# CH32M030 register map
Vendor: WCH Ltd.; File version: 1.1
CH32M030 View File
Registers are 32-bit, read-write, reset 0x0 unless marked. A register's access mark holds for its fields unless they carry their own. Offsets are from the block's base; lines under a group give offsets from that group; [hi:lo] are bit positions; {n}, {i} and the like mark numbered series; 'fields as' and 'values as' point back to an identical list; <NAME> marks a mode.

## Memory map
0x1FFFF3E0 ESIG size 0x14 — Device electronic signature
0x40000000 TIM2 size 0x400 — General purpose timer
0x40000400 TIM3 size 0x400 — Streamlined Timer
0x40002C00 WWDG size 0x400 — Window watchdog
0x40005400 I2C1 size 0x400 — Inter integrated circuit
0x40007000 PWR size 0x400 — Power control
0x40010000 AFIO size 0x400 — Alternate function I/O
0x40010400 EXTI size 0x400
0x40010800 GPIOA size 0x400 — General purpose I/O
0x40010C00 GPIOB size 0x400
0x40011000 GPIOC size 0x400
0x40012400 ADC1 size 0x400 — Analog to digital converter
0x40012C00 TIM1 size 0x400 — Advanced timer
0x40013000 SPI1 size 0x400 — Serial peripheral interface
0x40013800 UART1 size 0x400 — Universal asynchronous receiver transmitter
0x40020000 DMA1 size 0x400 — DMA1 controller
0x40021000 RCC size 0x400 — Reset and clock control
0x40022000 FLASH size 0x400
0x40023400 USBFS size 0x400 — USB full speed host/equipment control register
0x40023800 EXTEN size 0x400 — Extend configuration
0x40024000 USBPD0 size 0x3FF — USBPD configuration
0x40024400 USBPD1 size 0x3FF
0x40024800 OPA size 0x400 — OPA_CMP
0xE000D000 DBG size 0x400 — Debug support
0xE000E000 PFIC size 0x1100 — Programmable Fast Interrupt Controller

## Interrupts
16 WWDG — Window Watchdog interrupt
17 OPA — OPA and CMP global interrupt
18 FLASH — Flash global interrupt
19 RCC — Reset and clock control interrupt
20 EXTI7_0 (EXTI) — EXTI Line[7:0] interrupt
21 AWU (PWR) — AWU global interrupt
22 DMA1_Channel1 (DMA1) — DMA1 Channel 1 global interrupt
23 DMA1_Channel2 (DMA1) — DMA1 Channel 2 global interrupt
24 DMA1_Channel3 (DMA1) — DMA1 Channel 3 global interrupt
25 DMA1_Channel4 (DMA1) — DMA1 Channel 4 global interrupt
26 DMA1_Channel5 (DMA1) — DMA1 Channel 5 global interrupt
27 DMA1_Channel6 (DMA1) — DMA1 Channel 6 global interrupt
28 DMA1_Channel7 (DMA1) — DMA1 Channel 7 global interrupt
29 ADC (ADC1) — ADC global interrupt
30 I2C1_EV (I2C1) — I2C1 event interrupt
31 I2C1_ER (I2C1) — I2C1 error interrupt
32 UART1 — UART1 global interrupt
33 EXTI15_8 (EXTI) — EXTI Line[15:8] interrupt
34 TIM1BRK (TIM1) — TIM1 Break interrupt
35 TIM1UP (TIM1) — TIM1 Update interrupt
36 TIM1TRG (TIM1) — TIM1 Trigger and Commutation interrupts
37 TIM1CC (TIM1) — TIM1 Capture Compare interrupt
38 TIM2 — TIM2 global interrupt
39 USBPD0 — USBPD global interrupt
40 USBPD0WakeUP (USBPD0) — USBPD0 WakeUP global interrupt
41 USBPD1 — USBPD1 global interrupt
42 USBPD1WakeUP (USBPD1) — USBPD1 WakeUP interrupt
43 TIM3 — TIM3 global interrupt
44 SPI1 — SPI1 global interrupt
45 USBFS — USBFS global interrupt
46 USBFSWakeUP (USBFS) — USBFS wake-up interrupt

## PWR — Power control
Base 0x40007000
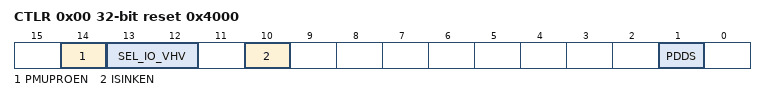
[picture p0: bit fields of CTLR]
0x00 CTLR reset 0x4000 — Power control register (PWR_CTRL)
  [14] PMUPROEN — PMU over-temperature protection Enable
  [13:12] SEL_IO_VHV — PB4 function Selection
  [10] ISINKEN — ISINK Enable
  [1] PDDS — Power Down Deep Sleep
0x08 AWUCSR — Automatic wake-up control state register (PWR_AWUCSR)
  [1] AWUEN — Automatic wake-up enable
0x0C AWUWR — Automatic wake window comparison value register (PWR_AWUWR)
  [3:0] AWUWR — AWU window value

## EXTEN — Extend configuration
Base 0x40023800
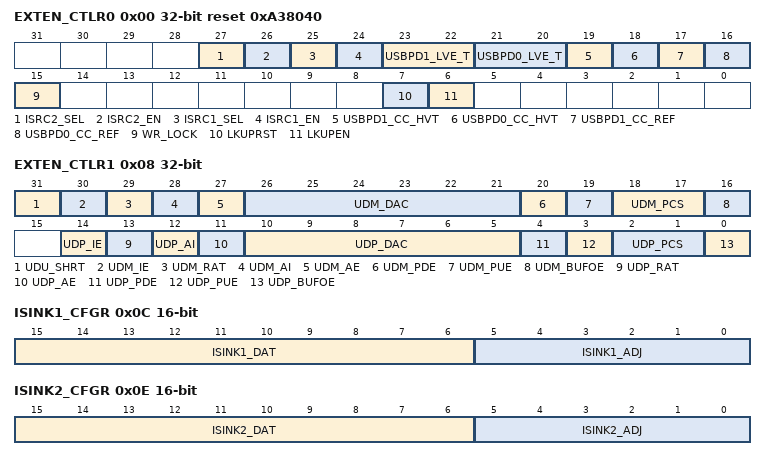
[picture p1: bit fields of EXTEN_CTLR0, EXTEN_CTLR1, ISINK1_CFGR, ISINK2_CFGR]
0x00 EXTEN_CTLR0 reset 0xA38040 — Configure the extended control register 0
  [27] ISRC2_SEL — Source current 2 selection
  [26] ISRC2_EN — Source current 2 enable
  [25] ISRC1_SEL — Source current 1 selection
  [24] ISRC1_EN — Source current 1 enable
  [23:22] USBPD1_LVE_T — CC pin of USBPD1 1.12V output Tr,Tf difference adjustment
  [21:20] USBPD0_LVE_T — CC pin of USBPD0 1.12V output Tr,Tf difference adjustment
  [19] USBPD1_CC_HVT — USBPD1 CC pin high threshold input mode enabled
  [18] USBPD0_CC_HVT — USBPD0 CC pin high threshold input mode enabled
  [17] USBPD1_CC_REF — USBPD1 CC pin analog reference enable
  [16] USBPD0_CC_REF — USBPD0 CC pin analog reference enable
  [15] WR_LOCK — Control register 0 and register 1 for configuration locking
  [7] LKUPRST — LOCKUP RESET
  [6] LKUPEN — LOCKUP_Enable
0x04 EXTEN_KEYR wo — Configure unlock register
  [0] KEYR — Control register 0 and register 1 for configuration unlocking
0x08 EXTEN_CTLR1 — Configure the extended control register 1
  [31] UDU_SHRT — UDP pin and UDM pin are shorted to enable
  [30] UDM_IE — UDM pin is input enabled when acting as a GPIO
  [29] UDM_RAT — UDM pin speed selection
  [28] UDM_AI — Output of the UDM pin comparator DAC_BUF
  [27] UDM_AE — Enable of the UDM pin buffer/comparator DAC_BUF
  [26:21] UDM_DAC — UPM port DAC data/programmable pull-down resistor and pull-up resistor data
  [20] UDM_PDE — UPM port DAC and programmable pull-down and pull-up mode selection
  [19] UDM_PUE — UPM port DAC and programmable pull-down and pull-up mode selection
  [18:17] UDM_PCS — Select pull-up current or pull-down current built into the UDM pin
  [16] UDM_BUFOE — UDM pin DAC_BUF output enable
  [14] UDP_IE — UDP pin is input enabled when acting as a GPIO
  [13] UDP_RAT — UDP pin speed selection
  [12] UDP_AI — Output of the UDP pin comparator DAC_BUF
  [11] UDP_AE — Enable of the UDP pin buffer/comparator DAC_BUF
  [10:5] UDP_DAC — UPD port DAC data/programmable pull-down resistor and pull-up resistor data
  [4] UDP_PDE — UPD port DAC and programmable pull-down and pull-up mode selection
  [3] UDP_PUE — UPD port DAC and programmable pull-down and pull-up mode selection
  [2:1] UDP_PCS — Select pull-up current or pull-down current built into the UDP pin
  [0] UDP_BUFOE — UDP pin DAC_BUF output enable
0x0C ISINK1_CFGR 16-bit ro — ISINK1 configuration register
  [15:6] ISINK1_DAT — Sink current 1 programmable data bit
  [5:0] ISINK1_ADJ — Sink current 1 calibration value
0x0E ISINK2_CFGR 16-bit ro — ISINK2 configuration register
  [15:6] ISINK2_DAT — Sink current 2 programmable data bit
  [5:0] ISINK2_ADJ — Sink current 2 calibration value
